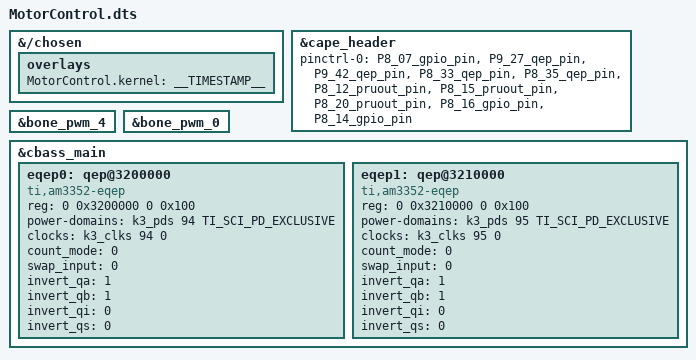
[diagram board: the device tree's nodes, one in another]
// SPDX-License-Identifier: GPL-2.0
/*
 * Copyright (C) 2022 Jason Kridner, BeagleBoard.org Foundation
 */

/dts-v1/;
/plugin/;

#include <dt-bindings/gpio/gpio.h>
#include <dt-bindings/interrupt-controller/arm-gic.h>
#include <dt-bindings/interrupt-controller/irq.h>
#include <dt-bindings/pinctrl/k3.h>
#include <dt-bindings/board/k3-j721e-bone-pins.h>
#include <dt-bindings/soc/ti,sci_pm_domain.h>
#include <dt-bindings/input/linux-event-codes.h>
&{/chosen} {
	overlays {
		MotorControl.kernel = __TIMESTAMP__;
	};
};

&cape_header {
	pinctrl-names = "default";
	pinctrl-0 = <
		&P8_07_gpio_pin		/* GPIO0_bit15 */
		&P9_27_qep_pin		/* EQEP0_B */
		&P9_42_qep_pin		/* EQEP0_A */
		&P8_33_qep_pin		/* EQEP1_B */
		&P8_35_qep_pin		/* EQEP1_A */
		&P8_12_pruout_pin	/* Motor control Direction bit PRU0 */
		&P8_15_pruout_pin   /* APWM mode Motor control PWM */
        &P8_20_pruout_pin   /* __r30 bit 13 toggle pin */
		&P8_16_gpio_pin     /* GPIO0_62 Scope debug pin PRU0 */
		&P8_14_gpio_pin	    /* GPIO0_75 Scope debug pin PRU1 */
	>;
};

&bone_pwm_4 {
	status = "okay"; /* EHRPWM4-B on P9-25 */
};

&bone_pwm_0 {
	status = "okay";
};

&cbass_main {
	#address-cells = <2>;
	#size-cells = <2>;

	/* TODO: the base for this should be in the board DT */
	eqep0: qep@3200000 {
		compatible = "ti,am3352-eqep";
		reg = <0 0x3200000 0 0x100>;
		power-domains = <&k3_pds 94 TI_SCI_PD_EXCLUSIVE>;
		clocks = <&k3_clks 94 0>;
		clock-names = "eqep0-ficlk";
		count_mode = <0>;
		swap_input = <0>;
		invert_qa = <1>;
		invert_qb = <1>;
		invert_qi = <0>;
		invert_qs = <0>;
	};

	eqep1: qep@3210000 {
		compatible = "ti,am3352-eqep";
		reg = <0 0x3210000 0 0x100>;
		power-domains = <&k3_pds 95 TI_SCI_PD_EXCLUSIVE>;
		clocks = <&k3_clks 95 0>;
		clock-names = "eqep1-ficlk";
		count_mode = <0>;
		swap_input = <0>;
		invert_qa = <1>;
		invert_qb = <1>;
		invert_qi = <0>;
		invert_qs = <0>;
	};
};
